VERSION "teryx"

NS_ :

BS_:

BU_: PI_DASH PICO_BOX SHINEGLE BENCH

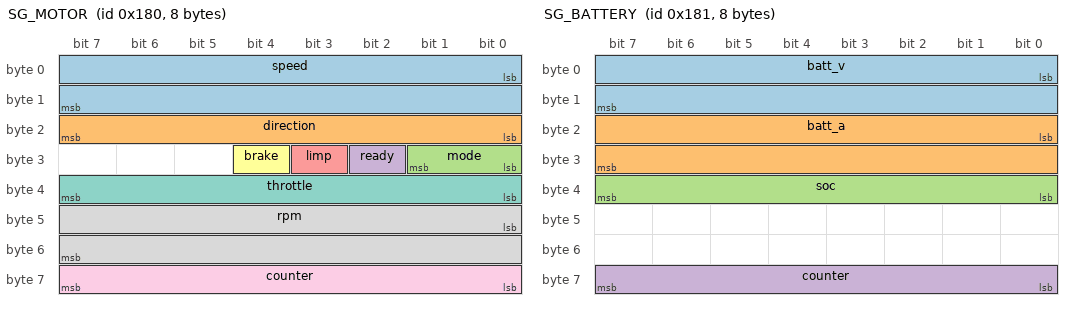
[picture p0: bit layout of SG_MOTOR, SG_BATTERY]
BO_ 384 SG_MOTOR: 8 SHINEGLE
 SG_ speed : 0|16@1+ (0.1,0) [0|6553.5] "km/h" Vector__XXX
 SG_ direction : 16|8@1+ (1,0) [0|255] "" Vector__XXX
 SG_ mode : 24|2@1+ (1,0) [0|3] "" Vector__XXX
 SG_ ready : 26|1@1+ (1,0) [0|1] "" Vector__XXX
 SG_ limp : 27|1@1+ (1,0) [0|1] "" Vector__XXX
 SG_ brake : 28|1@1+ (1,0) [0|1] "" Vector__XXX
 SG_ throttle : 32|8@1+ (1,0) [0|255] "%" Vector__XXX
 SG_ rpm : 40|16@1- (1,0) [-32768|32767] "rpm" Vector__XXX
 SG_ counter : 56|8@1+ (1,0) [0|255] "" Vector__XXX

BO_ 385 SG_BATTERY: 8 SHINEGLE
 SG_ batt_v : 0|16@1+ (0.1,0) [0|6553.5] "V" Vector__XXX
 SG_ batt_a : 16|16@1- (0.1,0) [-3276.8|3276.7] "A" Vector__XXX
 SG_ soc : 32|8@1+ (1,0) [0|255] "%" Vector__XXX
 SG_ counter : 56|8@1+ (1,0) [0|255] "" Vector__XXX

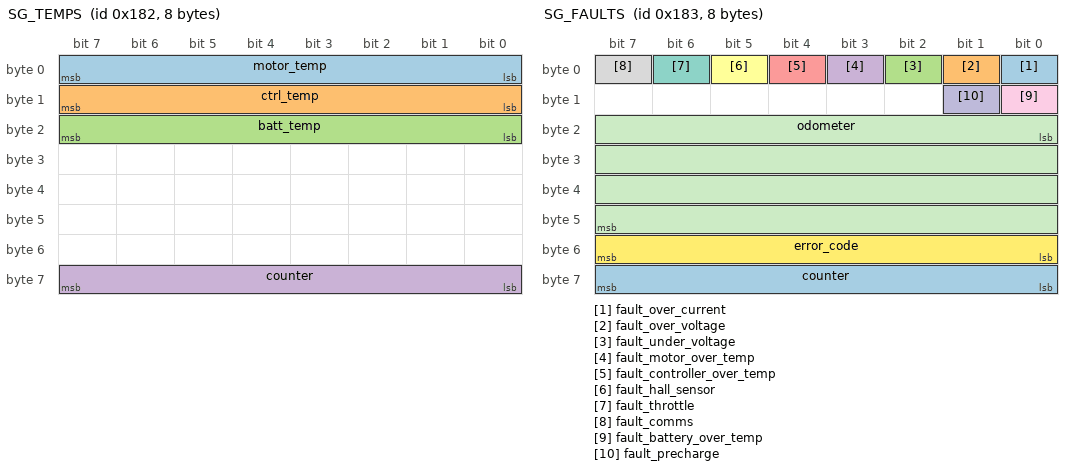
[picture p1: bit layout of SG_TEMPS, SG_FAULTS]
BO_ 386 SG_TEMPS: 8 SHINEGLE
 SG_ motor_temp : 0|8@1+ (1,-40) [-40|215] "C" Vector__XXX
 SG_ ctrl_temp : 8|8@1+ (1,-40) [-40|215] "C" Vector__XXX
 SG_ batt_temp : 16|8@1+ (1,-40) [-40|215] "C" Vector__XXX
 SG_ counter : 56|8@1+ (1,0) [0|255] "" Vector__XXX

BO_ 387 SG_FAULTS: 8 SHINEGLE
 SG_ fault_over_current : 0|1@1+ (1,0) [0|1] "" Vector__XXX
 SG_ fault_over_voltage : 1|1@1+ (1,0) [0|1] "" Vector__XXX
 SG_ fault_under_voltage : 2|1@1+ (1,0) [0|1] "" Vector__XXX
 SG_ fault_motor_over_temp : 3|1@1+ (1,0) [0|1] "" Vector__XXX
 SG_ fault_controller_over_temp : 4|1@1+ (1,0) [0|1] "" Vector__XXX
 SG_ fault_hall_sensor : 5|1@1+ (1,0) [0|1] "" Vector__XXX
 SG_ fault_throttle : 6|1@1+ (1,0) [0|1] "" Vector__XXX
 SG_ fault_comms : 7|1@1+ (1,0) [0|1] "" Vector__XXX
 SG_ fault_battery_over_temp : 8|1@1+ (1,0) [0|1] "" Vector__XXX
 SG_ fault_precharge : 9|1@1+ (1,0) [0|1] "" Vector__XXX
 SG_ odometer : 16|32@1+ (0.1,0) [0|429496729.5] "km" Vector__XXX
 SG_ error_code : 48|8@1+ (1,0) [0|255] "" Vector__XXX
 SG_ counter : 56|8@1+ (1,0) [0|255] "" Vector__XXX

CM_ "Shinegle SG1202 layout for Teryx OS. PLACEHOLDER: made up so the sim and dash can be built before the real bus is decoded. Replace this file with the one from: python -m teryx decode analyse (see docs/shinegle-decode.md).";
CM_ BO_ 384 "PLACEHOLDER layout. Bytes 0-2 are what the Pico reads for its speed interlocks.";
CM_ BO_ 385 "PLACEHOLDER layout.";
CM_ BO_ 386 "PLACEHOLDER layout.";
CM_ BO_ 387 "PLACEHOLDER layout.";
CM_ SG_ 385 batt_a "+ = draw, - = regen";
CM_ SG_ 387 fault_over_current "Motor over current";
CM_ SG_ 387 fault_over_voltage "Battery voltage too high";
CM_ SG_ 387 fault_under_voltage "Battery voltage too low";
CM_ SG_ 387 fault_motor_over_temp "Motor too hot";
CM_ SG_ 387 fault_controller_over_temp "Controller too hot";
CM_ SG_ 387 fault_hall_sensor "Motor position sensor fault";
CM_ SG_ 387 fault_throttle "Throttle fault";
CM_ SG_ 387 fault_comms "Controller comms fault";
CM_ SG_ 387 fault_battery_over_temp "Battery too hot";
CM_ SG_ 387 fault_precharge "Precharge fault";
CM_ SG_ 387 error_code "Controller ErrorCode, same number as the LED flash count (0 or 1 = no fault). Text in config/shinegle-faults.yaml";

BA_DEF_ BO_ "GenMsgCycleTime" INT 0 65535;
BA_DEF_DEF_ "GenMsgCycleTime" 0;
BA_ "GenMsgCycleTime" BO_ 384 50;
BA_ "GenMsgCycleTime" BO_ 385 100;
BA_ "GenMsgCycleTime" BO_ 386 500;
BA_ "GenMsgCycleTime" BO_ 387 200;

VAL_ 384 direction 0 "neutral" 1 "forward" 2 "reverse" ;
VAL_ 384 mode 0 "eco" 1 "normal" 2 "sport" ;
